# STM32WL5X_CM0P register map
File version: 2.1
CPU: CM0 r0p1, little endian, MPU, no FPU, 4 interrupt priority bits
Registers are 32-bit, read-write, reset 0x0 unless marked. A register's access mark holds for its fields unless they carry their own. Offsets are from the block's base; [hi:lo] are bit positions; {n}, {i} and the like mark numbered series.

## RNG — True random number generator
Base 0x58001000
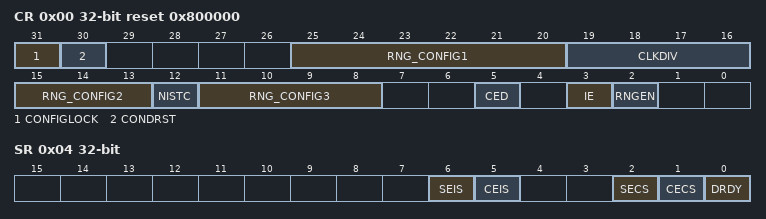
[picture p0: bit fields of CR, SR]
0x00 CR reset 0x800000 — control register
  [31] CONFIGLOCK
    0=Enabled (Writes to the RNG_CR configuration bits [29:4] are allowed); 1=Disabled (Writes to the RNG_CR configuration bits [29:4] are ignored until the next RNG reset)
  [30] CONDRST — Conditioning soft reset
  [25:20] RNG_CONFIG1
    15=ConfigA (Recommended value for config A (NIST certifiable)); 24=ConfigB (Recommended value for config B (not NIST certifiable))
  [19:16] CLKDIV
    0=Div1 (Internal RNG clock after divider is similar to incoming RNG clock); 1=Div2 (Divide RNG clock by 2^1); 2=Div4 (Divide RNG clock by 2^2); 3=Div8 (Divide RNG clock by 2^3); 4=Div16 (Divide RNG clock by 2^4); 5=Div32 (Divide RNG clock by 2^5); 6=Div64 (Divide RNG clock by 2^6); 7=Div128 (Divide RNG clock by 2^7); 8=Div256 (Divide RNG clock by 2^8); 9=Div512 (Divide RNG clock by 2^9); 10=Div1024 (Divide RNG clock by 2^10); 11=Div2048 (Divide RNG clock by 2^11); 12=Div4096 (Divide RNG clock by 2^12); 13=Div8192 (Divide RNG clock by 2^13); 14=Div16384 (Divide RNG clock by 2^14); 15=Div32768 (Divide RNG clock by 2^15)
  [15:13] RNG_CONFIG2
    0=ConfigA_B (Recommended value for config A and B)
  [12] NISTC
    0=Default (Hardware default values for NIST compliant RNG. In this configuration per 128-bit output two conditioning loops are performed and 256 bits of noise source are used); 1=Custom values for NIST compliant RNG
  [11:8] RNG_CONFIG3
    0=ConfigB (Recommended value for config B (not NIST certifiable)); 13=ConfigA (Recommended value for config A (NIST certifiable))
  [5] CED — Interrupt Enable
    0=Enabled (Clock error detection is enabled); 1=Disabled (Clock error detection is disabled)
  [3] IE — Interrupt Enable
    0=Disabled (RNG interrupt is disabled); 1=Enabled (RNG interrupt is enabled)
  [2] RNGEN — True random number generator enable
    0=Disabled (Random number generator is disabled); 1=Enabled (Random number generator is enabled)
0x04 SR access per field — status register
  [6] SEIS rw write-0-clears — Seed error interrupt status
    on write: 0=Clear flag | on read: 0=No faulty sequence detected; 1=Fault (At least one faulty sequence has been detected. See **SECS** bit description for details. An interrupt is pending if IE = 1 in the RNG_CR register.)
  [5] CEIS rw write-0-clears — Clock error interrupt status
    on write: 0=Clear flag | on read: 0=Correct (The RNG clock is correct); 1=Slow (The RNG has been detected too slow An interrupt is pending if IE = 1 in the RNG_CR register)
  [2] SECS ro — Seed error current status
    0=No faulty sequence has currently been detected. If the SEIS bit is set, this means that a faulty sequence was detected and the situation has been recovered.; 1=Fault (At least one faulty sequence has been detected - see ref manual for details)
  [1] CECS ro — Clock error current status
    0=Correct (The RNG clock is correct. If the CEIS bit is set, this means that a slow clock was detected and the situation has been recovered.); 1=Slow (The RNG clock is too slow)
  [0] DRDY ro — Data Ready
    0=Invalid (The RNG_DR register is not yet valid, no random data is available); 1=Valid (The RNG_DR register contains valid random data. Once the RNG_DR register has been read, this bit returns to 0 until a new random value is generated.)
0x08 DR ro — data register
  [31:0] RNDATA — Random data
0x10 HTCR reset 0x5A4E — health test control register
  [31:0] HTCFG — health test configuration
    0xAA74=Recommended value for RNG certification (0x0000_AA74); 0x17590ABC=Magic number to be written before any write (0x1759_0ABC)

## TZIC — TrustZone Interrupt Control
Base 0x58004800
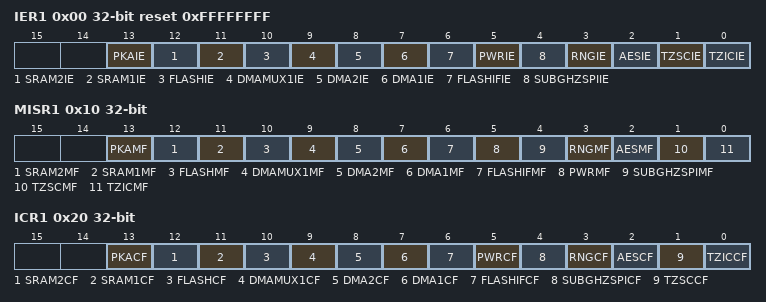
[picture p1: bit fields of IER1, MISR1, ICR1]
0x00 IER1 reset 0xFFFFFFFF — TZIC interrupt enable register 1
  [13] PKAIE, [12] SRAM2IE, [11] SRAM1IE, [10] FLASHIE, [9] DMAMUX1IE, [8] DMA2IE, [7] DMA1IE, [6] FLASHIFIE, [5] PWRIE, [4] SUBGHZSPIIE, [3] RNGIE, [2] AESIE, [1] TZSCIE, [0] TZICIE
0x10 MISR1 ro — TZIC status register 1
  [13] PKAMF, [12] SRAM2MF, [11] SRAM1MF, [10] FLASHMF, [9] DMAMUX1MF, [8] DMA2MF, [7] DMA1MF, [6] FLASHIFMF, [5] PWRMF, [4] SUBGHZSPIMF, [3] RNGMF, [2] AESMF, [1] TZSCMF, [0] TZICMF
0x20 ICR1 — TZIC interrupt status clear register 1
  [13] PKACF, [12] SRAM2CF, [11] SRAM1CF, [10] FLASHCF, [9] DMAMUX1CF, [8] DMA2CF, [7] DMA1CF, [6] FLASHIFCF, [5] PWRCF, [4] SUBGHZSPICF, [3] RNGCF, [2] AESCF, [1] TZSCCF, [0] TZICCF

## TZSC — Global TrustZone Controller
Base 0x58004400
0x00 CR — TZSC control register
  [0] LCK
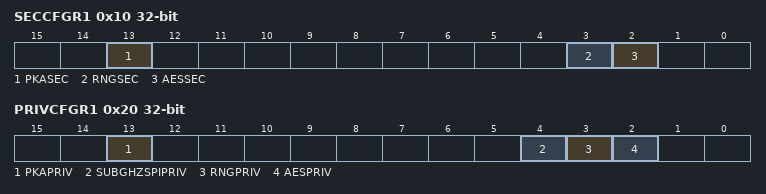
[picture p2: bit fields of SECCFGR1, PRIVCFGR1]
0x10 SECCFGR1 — TZSC security configuration register
  [13] PKASEC, [3] RNGSEC, [2] AESSEC
0x20 PRIVCFGR1 — TZSC privilege configuration register 1
  [13] PKAPRIV, [4] SUBGHZSPIPRIV, [3] RNGPRIV, [2] AESPRIV
{0x128+8i} MPCWM{i}_UPWMR reset 0xFFF0000 (i=1..3) — Unprivileged Water Mark {i} register
  [27:16] LGTH
0x134 MPCWM1_UPWWMR reset 0xFFF0000 — Unprivileged Writable Water Mark 1 register
  [27:16] LGTH — Define the length of Flash Unprivileged Writable area, in 2

## VREFBUF — Voltage reference buffer
Base 0x40010030
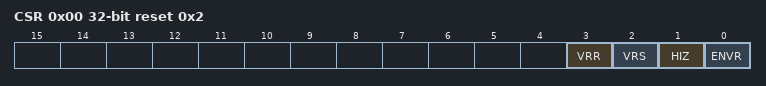
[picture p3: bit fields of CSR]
0x00 CSR access per field reset 0x2 — control and status register
  [3] VRR ro — Voltage reference buffer ready
    0=NotReady (The voltage reference buffer output is not ready); 1=Ready (The voltage reference buffer output reached the requested level)
  [2] VRS rw — Voltage reference scale
    0=V2_048 (Voltage reference set to VREF_OUT1 (around 2.048 V)); 1=V2_5 (Voltage reference set to VREF_OUT2 (around 2.5 V))
  [1] HIZ rw — High impedance mode
    0=Connected (VREF+ pin is internally connected to the voltage reference buffer output); 1=HighZ (VREF+ pin is high impedance)
  [0] ENVR rw — Voltage reference buffer mode enable
    0=Disabled (Internal voltage reference mode disable (external voltage reference mode)); 1=Enabled (Internal voltage reference mode (reference buffer enable or hold mode) enable)
0x04 CCR — calibration control register
  [5:0] TRIM — Trimming code

## WWDG — System window watchdog
Base 0x40002C00
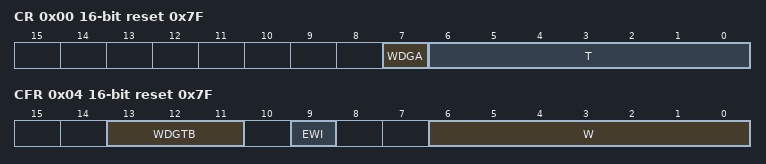
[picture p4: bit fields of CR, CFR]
0x00 CR 16-bit reset 0x7F — Control register
  [7] WDGA — Activation bit
    0=Disabled (Watchdog disabled); 1=Enabled (Watchdog enabled)
  [6:0] T — 7-bit counter (MSB to LSB)
0x04 CFR 16-bit access not given reset 0x7F — Configuration register
  [13:11] WDGTB — Timer base
    0=Div1 (Counter clock (PCLK1 div 4096) div 1); 1=Div2 (Counter clock (PCLK1 div 4096) div 2); 2=Div4 (Counter clock (PCLK1 div 4096) div 4); 3=Div8 (Counter clock (PCLK1 div 4096) div 8)
  [9] EWI wo — Early wakeup interrupt
    1=Enable (interrupt occurs whenever the counter reaches the value 0x40)
  [6:0] W rw — 7-bit window value
0x08 SR 16-bit — Status register
  [0] EWIF write-0-clears — Early wakeup interrupt flag
    on read: 0=Finished (The EWI Interrupt Service Routine has been serviced); 1=Pending (The EWI Interrupt Service Routine has been triggered) | on write: 0=Finished (The EWI Interrupt Service Routine has been serviced)
